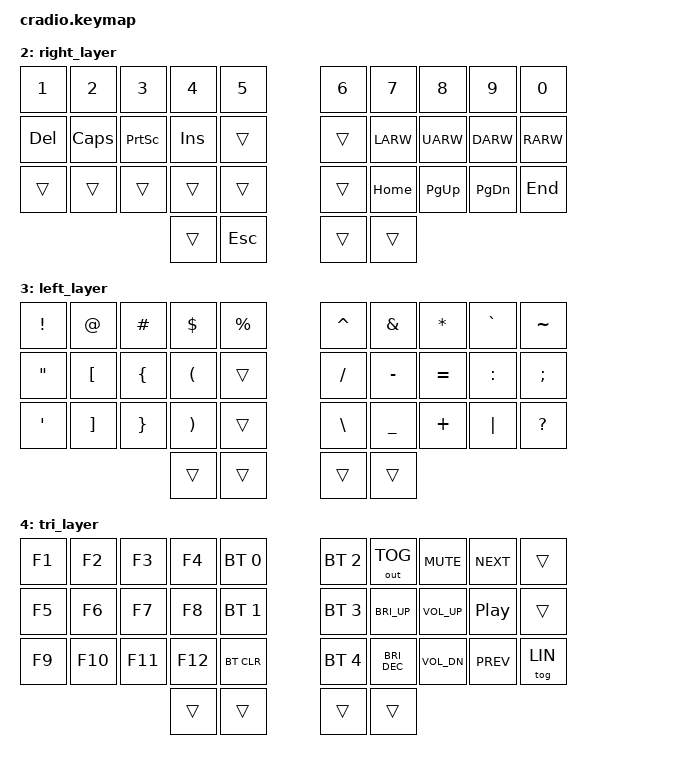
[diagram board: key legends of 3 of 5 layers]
// Copyright (c) 2022 The ZMK Contributors
// SPDX-License-Identifier: MIT

#include <behaviors.dtsi>
#include <dt-bindings/zmk/keys.h>
#include <dt-bindings/zmk/bt.h>
#include <dt-bindings/zmk/outputs.h>

#include "layers.dtsi"
#include "macros.dtsi"
#include "behaviors.dtsi"
#include "combos.dtsi"

// Home row mods macro
#define HRML(k2,k3,k4) &ht LCTRL k2  &ht LALT k3  &ht LGUI k4
#define HRMR(k1,k2,k3) &ht RGUI k1  &ht RALT k2 &ht RCTRL k3
#define LHRML(k2,k3,k4) &ht LGUI k2  &ht LALT k3  &ht LCTRL k4
#define LHRMR(k1,k2,k3) &ht RCTRL k1  &ht RALT k2  &ht RGUI k3

/ {
    conditional_layers {
        compatible = "zmk,conditional-layers";
        tri_layer {
            if-layers = <RIG LEF>;
            then-layer = <TRI>;
        };
    };

    keymap {
        compatible = "zmk,keymap";
        default_layer {
            bindings = <
        //╭──────────┬──────────┬──────────┬──────────┬──────────╮   ╭──────────┬──────────┬──────────┬──────────┬──────────╮
        //│  Q       │  W       │  E       │  R       │  T       │   │  Y       │  U       │  I       │  O       │  P       │
            &kp Q      &kp W      &kp E      &kp R      &kp T          &kp Y      &kp U      &kp I      &kp O      &kp P
        //├──────────┼──────────┼──────────┼──────────┼──────────┤   ├──────────┼──────────┼──────────┼──────────┼──────────┤
        //│  A       │ S |alt   │ D |ctrl  │  F |cmd  │  G       │   │  H       │  J |cmd  │  K |ctrl │  L |alt  │BACKSPACE │
            &kp A     HRML(S,         D,         F)     &kp G          &kp H      HRMR(J,        K,           L)   &kp BSPC
        //├──────────┼──────────┼──────────┼──────────┼──────────┤   ├──────────┼──────────┼──────────┼──────────┼──────────┤
        //│  Z       │  X       │  C       │  V       │  B       │   │  N       │  M       │ , <      │ . >      │ ENTER    │
            &kp Z      &kp X      &kp C      &kp V      &kp B          &kp N      &kp M      &kp COMMA  &kp DOT    &kp ENTER
        //╰──────────┴──────────┴──────────┼──────────┼──────────┤   ├──────────┼──────────┼──────────┴──────────┴──────────╯
                                           &lt LEF TAB  &kp LSHIFT    &kp SPACE  &lt RIG TAB
        //                                 ╰──────────┴──────────╯   ╰──────────┴──────────╯
            >;
        };

        // There may be some workaround in the future by pimping the OS with a hotkey replacement feature.
        // E.g. keysharp (if early access is sufficient) or simliar (autohotkey 2) 
        // This can imitate macOS keybind behavior:
        // https://www.autohotkey.com/boards/viewtopic.php?f=81&t=125220

        // GNOME / Wayland
        // show:
        // gsettings get org.gnome.desktop.input-sources xkb-options


        // bind compose to ralt
        // gsettings set org.gnome.desktop.input-sources xkb-options "['compose:ralt']"

        // Debian / X11:
        // setxkbmap -option compose:ralt

        linux_layer {
            bindings = <
        //╭──────────┬──────────┬──────────┬──────────┬──────────╮   ╭──────────┬──────────┬──────────┬──────────┬──────────╮
        //│  Q       │  W       │  E       │  R       │  T       │   │  Y       │  U       │  I       │  O       │  P       │
            &kp Q      &kp W      &kp E      &kp R      &kp T          &kp Y      &kp U      &kp I      &kp O      &kp P
        //├──────────┼──────────┼──────────┼──────────┼──────────┤   ├──────────┼──────────┼──────────┼──────────┼──────────┤
        //│  A       │  S       │  D       │  F       │  G       │   │  H       │  J       │  K       │  L       │BACKSPACE │
            &kp A    LHRML(S,         D,         F)     &kp G          &kp H      LHRMR(J,        K,         L)   &kp BSPC
        //├──────────┼──────────┼──────────┼──────────┼──────────┤   ├──────────┼──────────┼──────────┼──────────┼──────────┤
        //│  Z       │  X       │  C       │  V       │  B       │   │  N       │  M       │ , <      │ . >      │ ENTER    │
            &kp Z      &kp X      &kp C      &kp V      &kp B          &kp N      &kp M      &kp COMMA  &kp DOT    &kp ENTER
        //╰──────────┴──────────┴──────────┼──────────┼──────────┤   ├──────────┼──────────┼──────────┴──────────┴──────────╯
                                           &lt LEF TAB  &kp LSHIFT    &kp SPACE  &lt RIG TAB
        //                                 ╰──────────┴──────────╯   ╰──────────┴──────────╯
            >;
        };

        right_layer {
            bindings = <
        //╭──────────┬──────────┬──────────┬──────────┬──────────╮   ╭──────────┬──────────┬──────────┬──────────┬──────────╮
        //│ 1        │  2       │  3       │  4       │  5       │   │ 6        │ 7        │ 8        │ 9        │   0      │
            &kp N1    &kp N2     &kp N3     &kp N4     &kp N5          &kp N6     &kp N7     &kp N8     &kp N9      &kp N0
        //├──────────┼──────────┼──────────┼──────────┼──────────┤   ├──────────┼──────────┼──────────┼──────────┼──────────┤
        //│ DELETE   │ CapsLock │ PrintSc  │  INSERT  │          |   |          │ LEFT     │ UP       │ DOWN     │ RIGHT    │
            &kp DEL   &kp CAPS   &kp PSCRN  &kp INS     &trans         &trans     &kp LARW   &kp UARW   &kp DARW   &kp RARW 
        //├──────────┼──────────┼──────────┼──────────┼──────────┤   ├──────────┼──────────┼──────────┼──────────┼──────────┤
        //│          │          │          │          │          │   │          │ HOME     │ PAGE UP  │ PAGE DN  │ END      │
            &trans    &trans     &trans     &trans      &trans         &trans     &kp HOME   &kp PG_UP  &kp PG_DN  &kp END 
        //╰──────────┴──────────┴──────────┼──────────┼──────────┤   ├──────────┼──────────┼──────────┴──────────┴──────────╯
                                             &trans     &kp ESC        &trans     &trans
        //                                 ╰──────────┴──────────╯   ╰──────────┴──────────╯
            >;
        };

        left_layer {
            bindings = <
        //╭──────────┬──────────┬──────────┬──────────┬──────────╮   ╭──────────┬──────────┬──────────┬──────────┬──────────╮
        //│  !       │  @       │  #       │  $       │  %       │   │  ^       │  &       │  *       │  `       │  ~       │
            &kp EXCL   &kp AT     &kp HASH   &kp DLLR   &kp PRCNT      &kp CARET  &kp AMPS   &kp ASTRK  &kp GRAVE   &kp TILDE
        //├──────────┼──────────┼──────────┼──────────┼──────────┤   ├──────────┼──────────┼──────────┼──────────┼──────────┤
        //│  "       │  [       │  {       │  (       │          │   │   /      │  -       │  =       │     :    │  ;       │
            &kp DQT  &kp LBKT   &kp LBRC   &kp LPAR   &trans          &kp FSLH   &kp MINUS  &kp EQUAL  &kp COLON   &kp SEMI
        //├──────────┼──────────┼──────────┼──────────┼──────────┤   ├──────────┼──────────┼──────────┼──────────┼──────────┤
        //│  '       │  ]       │  }       │  )       │          │   │    \     │  _       │  +       │  │       │   ?      │
            &kp SQT     &kp RBKT   &kp RBRC   &kp RPAR   &trans         &kp BSLH   &kp UNDER  &kp PLUS   &kp PIPE  &kp QMARK
        //╰──────────┴──────────┴──────────┼──────────┼──────────┤   ├──────────┼──────────┼──────────┴──────────┴──────────╯
                                             &trans     &trans         &trans     &trans
        //                                 ╰──────────┴──────────╯   ╰──────────┴──────────╯
            >;
        };

        tri_layer {
            bindings = <
        //╭──────────┬──────────┬──────────┬───────────┬────────────╮   ╭────────────┬────────────┬────────────┬──────────┬──────────╮
        //│  F1      │  F2      │  F3      │  F4       │ PROFILE 0  │   │ PROFILE 2  │ TOGGLEOUT  │  VOL MUTE  │ NEXTSONG │       
            &kp F1     &kp F2     &kp F3     &kp F4     &bt BT_SEL 0     &bt BT_SEL 2  &out OUT_TOG  &kp C_MUTE  &kp C_NEXT  &trans
        //├──────────┼──────────┼──────────┼───────────┼────────────┤   ├────────────┼────────────┼────────────┼──────────┼──────────┤
        //│  F5      │  F6      │  F7      │  F8       │ PROFILE 1  │   │ PROFILE 3  │ INC BRIGHT │   VOL UP   │PAUSEMUSIC│            
            &kp F5     &kp F6     &kp F7     &kp F8     &bt BT_SEL 1     &bt BT_SEL 3  &kp C_BRI_UP &kp C_VOL_UP  &kp C_PP  &trans  
        //├──────────┼──────────┼──────────┼───────────┼────────────┤   ├────────────┼────────────┼────────────┼──────────┼──────────┤
        //│  F9      │  F10     │  F11     │  F12      │  CLEAR BT  │   │ PROFILE 4  │ DEC BRIGHT │   VOL DOWN │ PREVSONG │ Linux Layer
            &kp F9     &kp F10    &kp F11    &kp F12     &bt BT_CLR      &bt BT_SEL 4 &kp C_BRI_DEC &kp C_VOL_DN &kp C_PREV  &tog LIN 
        //╰──────────┴──────────┴──────────┼───────────┼────────────┤   ├────────────┼────────────┼────────────┴──────────┴──────────╯
                                                &trans     &trans         &trans     &trans
        //                                 ╰───────────┴────────────╯   ╰────────────┴────────────╯
            >;
        };
    };
};
